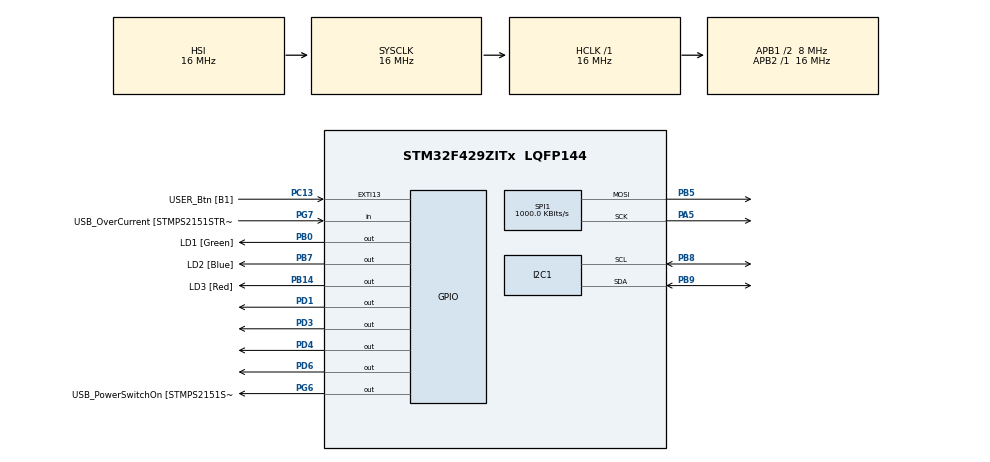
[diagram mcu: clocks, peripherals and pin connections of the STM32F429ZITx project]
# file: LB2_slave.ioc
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I2C1.OwnAddress=10
Mcu.Family=STM32F4
Mcu.Name=STM32F429ZITx
Mcu.Package=LQFP144
NVIC.I2C1_ER_IRQn=true\:0\:0\:false\:false\:true\:true\:true
NVIC.I2C1_EV_IRQn=true\:0\:0\:false\:false\:true\:true\:true
NVIC.PriorityGroup=NVIC_PRIORITYGROUP_4
NVIC.TIM3_IRQn=true\:0\:0\:false\:false\:true\:true\:true
PA1.GPIO_Label=RMII_REF_CLK [LAN8742A-CZ-TR_REFCLK0]
PA1.Signal=ETH_REF_CLK
PA10.GPIO_Label=USB_ID
PA10.Signal=USB_OTG_FS_ID
PA11.GPIO_Label=USB_DM
PA11.Signal=USB_OTG_FS_DM
PA12.GPIO_Label=USB_DP
PA12.Signal=USB_OTG_FS_DP
PA13.GPIO_Label=TMS
PA13.Signal=SYS_JTMS-SWDIO
PA14.GPIO_Label=TCK
PA14.Signal=SYS_JTCK-SWCLK
PA2.GPIO_Label=RMII_MDIO [LAN8742A-CZ-TR_MDIO]
PA2.Signal=ETH_MDIO
PA5.Mode=TX_Only_Simplex_Unidirect_Master
PA5.Signal=SPI1_SCK
PA7.GPIO_Label=RMII_CRS_DV [LAN8742A-CZ-TR_CRS_DV]
PA7.Signal=ETH_CRS_DV
PA8.GPIO_Label=USB_SOF [TP1]
PA8.Signal=USB_OTG_FS_SOF
PA9.GPIO_Label=USB_VBUS
PA9.Signal=USB_OTG_FS_VBUS
PB0.GPIO_Label=LD1 [Green]
PB0.Signal=GPIO_Output
PB13.GPIO_Label=RMII_TXD1 [LAN8742A-CZ-TR_TXD1]
PB13.Signal=ETH_TXD1
PB14.GPIO_Label=LD3 [Red]
PB14.Signal=GPIO_Output
PB5.Mode=TX_Only_Simplex_Unidirect_Master
PB5.Signal=SPI1_MOSI
PB7.GPIO_Label=LD2 [Blue]
PB7.Signal=GPIO_Output
PB8.GPIO_Pu=GPIO_PULLUP
PB8.Mode=I2C
PB8.Signal=I2C1_SCL
PB9.GPIO_Pu=GPIO_PULLUP
PB9.Mode=I2C
PB9.Signal=I2C1_SDA
PC1.GPIO_Label=RMII_MDC [LAN8742A-CZ-TR_MDC]
PC1.Signal=ETH_MDC
PC13.GPIO_Label=USER_Btn [B1]
PC13.Signal=GPXTI13
PC14/OSC32_IN.Signal=RCC_OSC32_IN
PC15/OSC32_OUT.Signal=RCC_OSC32_OUT
PC4.GPIO_Label=RMII_RXD0 [LAN8742A-CZ-TR_RXD0]
PC4.Signal=ETH_RXD0
PC5.GPIO_Label=RMII_RXD1 [LAN8742A-CZ-TR_RXD1]
PC5.Signal=ETH_RXD1
PD1.Signal=GPIO_Output
PD3.Signal=GPIO_Output
PD4.Signal=GPIO_Output
PD6.Signal=GPIO_Output
PD8.GPIO_Label=STLK_RX [STM32F103CBT6_PA3]
PD8.Signal=USART3_TX
PD9.GPIO_Label=STLK_TX [STM32F103CBT6_PA2]
PD9.Signal=USART3_RX
PG11.GPIO_Label=RMII_TX_EN [LAN8742A-CZ-TR_TXEN]
PG11.Signal=ETH_TX_EN
PG13.GPIO_Label=RMII_TXD0 [LAN8742A-CZ-TR_TXD0]
PG13.Signal=ETH_TXD0
PG6.GPIO_Label=USB_PowerSwitchOn [STMPS2151STR_EN]
PG6.Signal=GPIO_Output
PG7.GPIO_Label=USB_OverCurrent [STMPS2151STR_FAULT]
PG7.Signal=GPIO_Input
PH0/OSC_IN.GPIO_Label=MCO [STM32F103CBT6_PA8]
PH0/OSC_IN.Mode=HSE-External-Oscillator
PH0/OSC_IN.Signal=RCC_OSC_IN
PH1/OSC_OUT.Mode=HSE-External-Oscillator
PH1/OSC_OUT.Signal=RCC_OSC_OUT
ProjectManager.HeapSize=0x200
ProjectManager.StackSize=0x400
ProjectManager.TargetToolchain=MDK-ARM V5.32
RCC.48MHZClocksFreq_Value=48000000
RCC.AHBFreq_Value=16000000
RCC.APB1CLKDivider=RCC_HCLK_DIV2
RCC.APB1Freq_Value=8000000
RCC.APB1TimFreq_Value=16000000
RCC.APB2Freq_Value=16000000
RCC.APB2TimFreq_Value=16000000
RCC.CortexFreq_Value=16000000
RCC.HCLKFreq_Value=16000000
RCC.HSE_VALUE=8000000
RCC.HSI_VALUE=16000000
RCC.LSE_VALUE=32768
RCC.PLLMUL=RCC_PLL_MUL9
RCC.PRESCALERUSB=RCC_USBCLKSOURCE_PLL_DIV1_5
RCC.SYSCLKFreq_VALUE=16000000
RCC.SYSCLKSourceVirtual=RCC_SYSCLKSOURCE_PLLCLK
RCC.USBFreq_Value=48000000
RCC.VCOOutputFreq_Value=192000000
SPI1.BaudRatePrescaler=SPI_BAUDRATEPRESCALER_16
SPI1.CalculateBaudRate=1000.0 KBits/s
SPI1.Direction=SPI_DIRECTION_2LINES
SPI1.Mode=SPI_MODE_MASTER
SPI1.VirtualType=VM_MASTER
TIM3.Period=10000-1
TIM3.Prescaler=4-1
VP_TIM3_VS_ClockSourceINT.Mode=Internal
board=NUCLEO-F429ZI

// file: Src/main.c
/* USER CODE BEGIN Header */
/**
  ******************************************************************************
  * @file           : main.c
  * @brief          : Main program body
  ******************************************************************************
  * @attention
  *
  * <h2><center>&copy; Copyright (c) 2023 STMicroelectronics.
  * All rights reserved.</center></h2>
  *
  * This software component is licensed by ST under BSD 3-Clause license,
  * the "License"; You may not use this file except in compliance with the
  * License. You may obtain a copy of the License at:
  *                        opensource.org/licenses/BSD-3-Clause
  *
  ******************************************************************************
  */
/* USER CODE END Header */
#include "main.h"

I2C_HandleTypeDef hi2c1;

SPI_HandleTypeDef hspi1;

TIM_HandleTypeDef htim3;

/* USER CODE BEGIN PV */

int16_t gyro_data[3] = {0};

int16_t gyro_x = 0;
int16_t gyro_y = 0;
int16_t gyro_z = 0;

Pixel p1 = {16, 8};

uint8_t RxBuff[2];

/* USER CODE END PV */

void SystemClock_Config(void);
static void MX_GPIO_Init(void);
static void MX_I2C1_Init(void);
static void MX_SPI1_Init(void);
static void MX_TIM3_Init(void);

int main(void)
{

  /* MCU Configuration--------------------------------------------------------*/

  /* Reset of all peripherals, Initializes the Flash interface and the Systick. */
  HAL_Init();

  /* Configure the system clock */
  SystemClock_Config();

  /* Initialize all configured peripherals */
  MX_GPIO_Init();
  MX_I2C1_Init();
  MX_SPI1_Init();
  MX_TIM3_Init();
  /* USER CODE BEGIN 2 */
	HAL_TIM_Base_Start_IT(&htim3);

  /* USER CODE END 2 */

  /* Infinite loop */
  while (1)
  {

    /* USER CODE BEGIN 3 */

		HAL_I2C_Slave_Receive_IT(&hi2c1, RxBuff, 2);

		p1.x = RxBuff[0];
		p1.y = RxBuff[1];

  }
  /* USER CODE END 3 */
}

void SystemClock_Config(void)
{
  RCC_OscInitTypeDef RCC_OscInitStruct = {0};
  RCC_ClkInitTypeDef RCC_ClkInitStruct = {0};

  /** Configure the main internal regulator output voltage
  */
  __HAL_RCC_PWR_CLK_ENABLE();
  __HAL_PWR_VOLTAGESCALING_CONFIG(PWR_REGULATOR_VOLTAGE_SCALE3);
  /** Initializes the RCC Oscillators according to the specified parameters
  * in the RCC_OscInitTypeDef structure.
  */
  RCC_OscInitStruct.OscillatorType = RCC_OSCILLATORTYPE_HSI;
  RCC_OscInitStruct.HSIState = RCC_HSI_ON;
  RCC_OscInitStruct.HSICalibrationValue = RCC_HSICALIBRATION_DEFAULT;
  RCC_OscInitStruct.PLL.PLLState = RCC_PLL_NONE;
  if (HAL_RCC_OscConfig(&RCC_OscInitStruct) != HAL_OK)
  {
    Error_Handler();
  }
  /** Initializes the CPU, AHB and APB buses clocks
  */
  RCC_ClkInitStruct.ClockType = RCC_CLOCKTYPE_HCLK|RCC_CLOCKTYPE_SYSCLK
                              |RCC_CLOCKTYPE_PCLK1|RCC_CLOCKTYPE_PCLK2;
  RCC_ClkInitStruct.SYSCLKSource = RCC_SYSCLKSOURCE_HSI;
  RCC_ClkInitStruct.AHBCLKDivider = RCC_SYSCLK_DIV1;
  RCC_ClkInitStruct.APB1CLKDivider = RCC_HCLK_DIV2;
  RCC_ClkInitStruct.APB2CLKDivider = RCC_HCLK_DIV1;

  if (HAL_RCC_ClockConfig(&RCC_ClkInitStruct, FLASH_LATENCY_0) != HAL_OK)
  {
    Error_Handler();
  }
}

static void MX_I2C1_Init(void)
{

  hi2c1.Instance = I2C1;
  hi2c1.Init.ClockSpeed = 100000;
  hi2c1.Init.DutyCycle = I2C_DUTYCYCLE_2;
  hi2c1.Init.OwnAddress1 = 20;
  hi2c1.Init.AddressingMode = I2C_ADDRESSINGMODE_7BIT;
  hi2c1.Init.DualAddressMode = I2C_DUALADDRESS_DISABLE;
  hi2c1.Init.OwnAddress2 = 0;
  hi2c1.Init.GeneralCallMode = I2C_GENERALCALL_DISABLE;
  hi2c1.Init.NoStretchMode = I2C_NOSTRETCH_DISABLE;
  if (HAL_I2C_Init(&hi2c1) != HAL_OK)
  {
    Error_Handler();
  }
  /** Configure Analogue filter
  */
  if (HAL_I2CEx_ConfigAnalogFilter(&hi2c1, I2C_ANALOGFILTER_ENABLE) != HAL_OK)
  {
    Error_Handler();
  }
  /** Configure Digital filter
  */
  if (HAL_I2CEx_ConfigDigitalFilter(&hi2c1, 0) != HAL_OK)
  {
    Error_Handler();
  }

}

static void MX_SPI1_Init(void)
{

  /* SPI1 parameter configuration*/
  hspi1.Instance = SPI1;
  hspi1.Init.Mode = SPI_MODE_MASTER;
  hspi1.Init.Direction = SPI_DIRECTION_2LINES;
  hspi1.Init.DataSize = SPI_DATASIZE_8BIT;
  hspi1.Init.CLKPolarity = SPI_POLARITY_LOW;
  hspi1.Init.CLKPhase = SPI_PHASE_1EDGE;
  hspi1.Init.NSS = SPI_NSS_SOFT;
  hspi1.Init.BaudRatePrescaler = SPI_BAUDRATEPRESCALER_16;
  hspi1.Init.FirstBit = SPI_FIRSTBIT_MSB;
  hspi1.Init.TIMode = SPI_TIMODE_DISABLE;
  hspi1.Init.CRCCalculation = SPI_CRCCALCULATION_DISABLE;
  hspi1.Init.CRCPolynomial = 10;
  if (HAL_SPI_Init(&hspi1) != HAL_OK)
  {
    Error_Handler();
  }

}

static void MX_TIM3_Init(void)
{

  TIM_ClockConfigTypeDef sClockSourceConfig = {0};
  TIM_MasterConfigTypeDef sMasterConfig = {0};

  htim3.Instance = TIM3;
  htim3.Init.Prescaler = 4-1;
  htim3.Init.CounterMode = TIM_COUNTERMODE_UP;
  htim3.Init.Period = 10000-1;
  htim3.Init.ClockDivision = TIM_CLOCKDIVISION_DIV1;
  htim3.Init.AutoReloadPreload = TIM_AUTORELOAD_PRELOAD_DISABLE;
  if (HAL_TIM_Base_Init(&htim3) != HAL_OK)
  {
    Error_Handler();
  }
  sClockSourceConfig.ClockSource = TIM_CLOCKSOURCE_INTERNAL;
  if (HAL_TIM_ConfigClockSource(&htim3, &sClockSourceConfig) != HAL_OK)
  {
    Error_Handler();
  }
  sMasterConfig.MasterOutputTrigger = TIM_TRGO_RESET;
  sMasterConfig.MasterSlaveMode = TIM_MASTERSLAVEMODE_DISABLE;
  if (HAL_TIMEx_MasterConfigSynchronization(&htim3, &sMasterConfig) != HAL_OK)
  {
    Error_Handler();
  }

}

static void MX_GPIO_Init(void)
{
  GPIO_InitTypeDef GPIO_InitStruct = {0};

  /* GPIO Ports Clock Enable */
  __HAL_RCC_GPIOC_CLK_ENABLE();
  __HAL_RCC_GPIOH_CLK_ENABLE();
  __HAL_RCC_GPIOA_CLK_ENABLE();
  __HAL_RCC_GPIOB_CLK_ENABLE();
  __HAL_RCC_GPIOD_CLK_ENABLE();
  __HAL_RCC_GPIOG_CLK_ENABLE();

  /*Configure GPIO pin Output Level */
  HAL_GPIO_WritePin(GPIOB, LD1_Pin|LD3_Pin|LD2_Pin, GPIO_PIN_RESET);

  /*Configure GPIO pin Output Level */
  HAL_GPIO_WritePin(USB_PowerSwitchOn_GPIO_Port, USB_PowerSwitchOn_Pin, GPIO_PIN_RESET);

  /*Configure GPIO pin Output Level */
  HAL_GPIO_WritePin(GPIOD, GPIO_PIN_1|GPIO_PIN_3|GPIO_PIN_4|GPIO_PIN_6, GPIO_PIN_RESET);

  /*Configure GPIO pin : USER_Btn_Pin */
  GPIO_InitStruct.Pin = USER_Btn_Pin;
  GPIO_InitStruct.Mode = GPIO_MODE_IT_RISING;
  GPIO_InitStruct.Pull = GPIO_NOPULL;
  HAL_GPIO_Init(USER_Btn_GPIO_Port, &GPIO_InitStruct);

  /*Configure GPIO pins : RMII_MDC_Pin RMII_RXD0_Pin RMII_RXD1_Pin */
  GPIO_InitStruct.Pin = RMII_MDC_Pin|RMII_RXD0_Pin|RMII_RXD1_Pin;
  GPIO_InitStruct.Mode = GPIO_MODE_AF_PP;
  GPIO_InitStruct.Pull = GPIO_NOPULL;
  GPIO_InitStruct.Speed = GPIO_SPEED_FREQ_VERY_HIGH;
  GPIO_InitStruct.Alternate = GPIO_AF11_ETH;
  HAL_GPIO_Init(GPIOC, &GPIO_InitStruct);

  /*Configure GPIO pins : RMII_REF_CLK_Pin RMII_MDIO_Pin RMII_CRS_DV_Pin */
  GPIO_InitStruct.Pin = RMII_REF_CLK_Pin|RMII_MDIO_Pin|RMII_CRS_DV_Pin;
  GPIO_InitStruct.Mode = GPIO_MODE_AF_PP;
  GPIO_InitStruct.Pull = GPIO_NOPULL;
  GPIO_InitStruct.Speed = GPIO_SPEED_FREQ_VERY_HIGH;
  GPIO_InitStruct.Alternate = GPIO_AF11_ETH;
  HAL_GPIO_Init(GPIOA, &GPIO_InitStruct);

  /*Configure GPIO pins : LD1_Pin LD3_Pin LD2_Pin */
  GPIO_InitStruct.Pin = LD1_Pin|LD3_Pin|LD2_Pin;
  GPIO_InitStruct.Mode = GPIO_MODE_OUTPUT_PP;
  GPIO_InitStruct.Pull = GPIO_NOPULL;
  GPIO_InitStruct.Speed = GPIO_SPEED_FREQ_LOW;
  HAL_GPIO_Init(GPIOB, &GPIO_InitStruct);

  /*Configure GPIO pin : RMII_TXD1_Pin */
  GPIO_InitStruct.Pin = RMII_TXD1_Pin;
  GPIO_InitStruct.Mode = GPIO_MODE_AF_PP;
  GPIO_InitStruct.Pull = GPIO_NOPULL;
  GPIO_InitStruct.Speed = GPIO_SPEED_FREQ_VERY_HIGH;
  GPIO_InitStruct.Alternate = GPIO_AF11_ETH;
  HAL_GPIO_Init(RMII_TXD1_GPIO_Port, &GPIO_InitStruct);

  /*Configure GPIO pins : STLK_RX_Pin STLK_TX_Pin */
  GPIO_InitStruct.Pin = STLK_RX_Pin|STLK_TX_Pin;
  GPIO_InitStruct.Mode = GPIO_MODE_AF_PP;
  GPIO_InitStruct.Pull = GPIO_NOPULL;
  GPIO_InitStruct.Speed = GPIO_SPEED_FREQ_VERY_HIGH;
  GPIO_InitStruct.Alternate = GPIO_AF7_USART3;
  HAL_GPIO_Init(GPIOD, &GPIO_InitStruct);

  /*Configure GPIO pin : USB_PowerSwitchOn_Pin */
  GPIO_InitStruct.Pin = USB_PowerSwitchOn_Pin;
  GPIO_InitStruct.Mode = GPIO_MODE_OUTPUT_PP;
  GPIO_InitStruct.Pull = GPIO_NOPULL;
  GPIO_InitStruct.Speed = GPIO_SPEED_FREQ_LOW;
  HAL_GPIO_Init(USB_PowerSwitchOn_GPIO_Port, &GPIO_InitStruct);

  /*Configure GPIO pin : USB_OverCurrent_Pin */
  GPIO_InitStruct.Pin = USB_OverCurrent_Pin;
  GPIO_InitStruct.Mode = GPIO_MODE_INPUT;
  GPIO_InitStruct.Pull = GPIO_NOPULL;
  HAL_GPIO_Init(USB_OverCurrent_GPIO_Port, &GPIO_InitStruct);

  /*Configure GPIO pins : USB_SOF_Pin USB_ID_Pin USB_DM_Pin USB_DP_Pin */
  GPIO_InitStruct.Pin = USB_SOF_Pin|USB_ID_Pin|USB_DM_Pin|USB_DP_Pin;
  GPIO_InitStruct.Mode = GPIO_MODE_AF_PP;
  GPIO_InitStruct.Pull = GPIO_NOPULL;
  GPIO_InitStruct.Speed = GPIO_SPEED_FREQ_VERY_HIGH;
  GPIO_InitStruct.Alternate = GPIO_AF10_OTG_FS;
  HAL_GPIO_Init(GPIOA, &GPIO_InitStruct);

  /*Configure GPIO pin : USB_VBUS_Pin */
  GPIO_InitStruct.Pin = USB_VBUS_Pin;
  GPIO_InitStruct.Mode = GPIO_MODE_INPUT;
  GPIO_InitStruct.Pull = GPIO_NOPULL;
  HAL_GPIO_Init(USB_VBUS_GPIO_Port, &GPIO_InitStruct);

  /*Configure GPIO pins : PD1 PD3 PD4 PD6 */
  GPIO_InitStruct.Pin = GPIO_PIN_1|GPIO_PIN_3|GPIO_PIN_4|GPIO_PIN_6;
  GPIO_InitStruct.Mode = GPIO_MODE_OUTPUT_PP;
  GPIO_InitStruct.Pull = GPIO_NOPULL;
  GPIO_InitStruct.Speed = GPIO_SPEED_FREQ_LOW;
  HAL_GPIO_Init(GPIOD, &GPIO_InitStruct);

  /*Configure GPIO pins : RMII_TX_EN_Pin RMII_TXD0_Pin */
  GPIO_InitStruct.Pin = RMII_TX_EN_Pin|RMII_TXD0_Pin;
  GPIO_InitStruct.Mode = GPIO_MODE_AF_PP;
  GPIO_InitStruct.Pull = GPIO_NOPULL;
  GPIO_InitStruct.Speed = GPIO_SPEED_FREQ_VERY_HIGH;
  GPIO_InitStruct.Alternate = GPIO_AF11_ETH;
  HAL_GPIO_Init(GPIOG, &GPIO_InitStruct);

}

void Error_Handler(void)
{
  __disable_irq();
  while (1)
  {
  }
}

/************************ (C) COPYRIGHT STMicroelectronics *****END OF FILE****/
